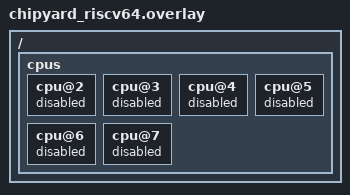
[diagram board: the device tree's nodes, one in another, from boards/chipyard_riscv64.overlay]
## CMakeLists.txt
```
# SPDX-License-Identifier: Apache-2.0
#
# Generic modelblaster harness. Build for a specific model+target by passing
# MODEL_DIR (where the generated C lives) and MODELBLASTER_BACKEND (the HW target):
#
#   west build -p -b spike_riscv64 modelblaster/harness -- \
#       -DMODEL_DIR=$PWD/modelblaster/examples/mlp/generated/scalar \
#       -DMODELBLASTER_BACKEND=scalar
#
# MODELBLASTER_BACKEND selects:
#   - the prj.conf overlay under modelblaster/harness/backends/<name>.conf
#   - the per-source compile flags applied to kernels.c
#   (both come from modelblaster/pipeline/backends.py — passed in via -D)
#
# Defaults to "scalar" if unset.

cmake_minimum_required(VERSION 3.20.0)

if(NOT DEFINED MODEL_DIR)
    message(FATAL_ERROR
        "MODEL_DIR not set. Pass -DMODEL_DIR=<absolute path to a generated/<target>/ dir>.")
endif()
get_filename_component(MODEL_DIR "${MODEL_DIR}" ABSOLUTE)
if(NOT IS_DIRECTORY "${MODEL_DIR}")
    message(FATAL_ERROR "MODEL_DIR='${MODEL_DIR}' is not a directory.")
endif()

if(NOT DEFINED MODELBLASTER_BACKEND)
    set(MODELBLASTER_BACKEND "scalar")
endif()

# Splice the backend prj.conf overlay BEFORE find_package(Zephyr) so its
# CONFIG_* lines reach Kconfig.
set(CONF_FILE "prj.conf")
set(_BACKEND_CONF "${CMAKE_CURRENT_LIST_DIR}/backends/${MODELBLASTER_BACKEND}.conf")
if(EXISTS "${_BACKEND_CONF}")
    list(APPEND CONF_FILE "${_BACKEND_CONF}")
else()
    message(FATAL_ERROR
        "MODELBLASTER_BACKEND='${MODELBLASTER_BACKEND}' but no overlay at ${_BACKEND_CONF}")
endif()

find_package(Zephyr REQUIRED HINTS $ENV{ZEPHYR_BASE})
project(modelblaster_harness)

foreach(_required model.c model.h kernels.c kernels.h weights.c weights.h buffers.c test_io.h test_io.S test_golden.bin)
    if(NOT EXISTS "${MODEL_DIR}/${_required}")
        message(FATAL_ERROR
            "MODEL_DIR='${MODEL_DIR}' is missing required file: ${_required}. "
            "Run modelblaster/pipeline/generate_skeleton.py and generate_kernels.py first.")
    endif()
endforeach()
# Test input blob(s): single-input models emit test_input.bin; multi-input
# models emit test_input0.bin, test_input1.bin, ... (each .incbin'd by
# test_io.S). Require at least one of the two forms to exist.
if(NOT EXISTS "${MODEL_DIR}/test_input.bin" AND NOT EXISTS "${MODEL_DIR}/test_input0.bin")
    message(FATAL_ERROR
        "MODEL_DIR='${MODEL_DIR}' has no test_input.bin or test_input0.bin. "
        "Run modelblaster/pipeline/generate_skeleton.py first.")
endif()
message(STATUS "modelblaster harness MODEL_DIR=${MODEL_DIR}  backend=${MODELBLASTER_BACKEND}")

target_sources(app PRIVATE
    src/main.c
    ${MODEL_DIR}/model.c
    ${MODEL_DIR}/kernels.c
    ${MODEL_DIR}/weights.c
    ${MODEL_DIR}/buffers.c
    ${MODEL_DIR}/test_io.S
)
set_source_files_properties(${MODEL_DIR}/test_io.S PROPERTIES LANGUAGE ASM)

# Big models (mlp_control's hidden layers, dronet's conv weights) push
# .sdata past the ±2KB window that the linker tries to fold into
# `gp`-relative loads via R_RISCV_GPREL_I, producing
# "relocation truncated to fit" against e.g. z_malloc_heap. Disable
# linker relaxation here — medany still gives ±2GB addressing, we just
# lose the gp-relative shortcut. No measurable code-size impact.
zephyr_link_libraries(-Wl,--no-relax)

# >2GB baked io only links under the RISC-V large code model
# (CONFIG_RISCV_CMODEL_LARGE), which fixes the C-side references. But the
# hand-written startup assembly (vector.S/reset.S/isr.S) uses fixed
# PC-relative addressing that -mcmodel=large does NOT rewrite, so if the
# giant io sits in .rodata (before .bss) it pushes gp/_kernel/z_interrupt_stacks
# past the startup asm's +/-2GiB reach and the link still truncates. When the
# large model is active, emit the io into .mb_bigio (test_io.S #ifdef
# MB_BIGIO_HIGH) and place that section ABOVE .bss (harness/bigio.ld). Default
# (medany) builds are untouched -> byte-identical.
# MB_NO_BIGIO_REORDER=1 opts out (io stays in .rodata) — e.g. io that fits
# under 2GiB, or XIP boards where io belongs in flash not RAM.
if(CONFIG_RISCV_CMODEL_LARGE AND NOT MB_NO_BIGIO_REORDER)
    target_compile_definitions(app PRIVATE MB_BIGIO_HIGH=1)
    zephyr_linker_sources(SECTIONS ${CMAKE_CURRENT_LIST_DIR}/bigio.ld)
    message(STATUS "modelblaster harness: CMODEL_LARGE active -> io in .mb_bigio placed above .bss")
endif()

target_include_directories(app PRIVATE
    src
    ${MODEL_DIR}
)

# Apply backend-specific compile flags ONLY to kernels.c so we don't perturb
# Zephyr's own build. Flags are passed in via -DMODELBLASTER_KERNEL_CFLAGS=...
# as a CMake list (semicolon-separated).
if(DEFINED MODELBLASTER_KERNEL_CFLAGS AND NOT "${MODELBLASTER_KERNEL_CFLAGS}" STREQUAL "")
    set_source_files_properties(
        ${MODEL_DIR}/kernels.c
        PROPERTIES COMPILE_OPTIONS "${MODELBLASTER_KERNEL_CFLAGS}"
    )
    message(STATUS "modelblaster harness kernel cflags=${MODELBLASTER_KERNEL_CFLAGS}")
endif()

# Opt-in: TACIT / L-Trace of just the model inference (brackets run_model with
# the encoder start/stop). Pass -DMB_TACIT_TRACE_MODEL=1 and run on the
# TACIT-enabled spike with `--trace=l`. See samples/tacit/TACIT_TRACING.md.
if(MB_TACIT_TRACE_MODEL)
    target_compile_definitions(app PRIVATE MB_TACIT_TRACE_MODEL=1)
    message(STATUS "modelblaster harness: TACIT model tracing enabled")
endif()
```

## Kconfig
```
# Application-level Kconfig for the ModelBlaster harness.
#
# Zephyr picks this up automatically when APPLICATION_SOURCE_DIR is this
# directory (see ZEPHYR/cmake/modules/kconfig.cmake L48-50). We use it to
# declare any project-local Kconfig symbols that aren't in the upstream
# Zephyr tree the workspace happens to ship, then source the standard
# Zephyr Kconfig so the rest of the build pulls in everything else.

# ---- ModelBlaster-local symbols ----

config RISCV_V_KERNEL_ONLY
	bool "Restrict V codegen to kernel files only"
	depends on RISCV_ISA_EXT_V
	default n
	help
	  Restrict V codegen to kernel files + arch/riscv/core/v.c only.
	  Without this, GCC auto-vectorizes struct-init/memset in vprintk,
	  libc, micro-ROS, broker, etc. via fractional-LMUL vector stores
	  — which on multi-hart Saturn FireSim makes scalar code paths
	  interrupt-corruptible (mid-V instruction preemption can clobber
	  scalar regs). We want V live ONLY inside the generated kernel
	  functions, where preemption is masked already (run_graph_b's
	  irq mask path).

	  Not required on single-hart spike runs (no preemption) but
	  must be y for FireSim multi-hart Saturn.

	  The actual enforcement (V codegen restriction) is opt-in: enabling
	  this symbol declares the intent and the build system / make rules
	  add -fno-tree-vectorize to the non-kernel TUs in the appropriate
	  passes. Upstream Zephyr doesn't have this option yet; tracked
	  under tmp/07_gotchas.md #9.

# ---- pull in standard Zephyr Kconfig ----

source "Kconfig.zephyr"
```

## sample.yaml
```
sample:
  description: Generated DNN inference harness (modelblaster flow)
  name: modelblaster_harness
common:
  tags: modelblaster dnn
  integration_platforms:
    - spike_riscv64
  harness: console
  harness_config:
    type: multi_line
    regex:
      - "=== MODELBLASTER_OUTPUT_BEGIN ==="
      - "=== MODELBLASTER_OUTPUT_END ==="
tests:
  sample.modelblaster.harness:
    tags: modelblaster
```

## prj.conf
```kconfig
# 4 MB main stack — large enough for im2col-style algorithms that allocate
# OH*OW * IC*KH*KW floats as a stack VLA. DroNet's worst case is about
# 295 KB; we leave plenty of headroom for larger models.
CONFIG_MAIN_STACK_SIZE=4194304
CONFIG_CBPRINTF_FP_SUPPORT=y
CONFIG_FPU=y
```

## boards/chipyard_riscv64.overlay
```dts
/*
 * DT overlay for FireSimGemminiAndOPUShuttleConfig.
 * Our SoC has only 2 Shuttle tiles, but chipyard-riscv64.dtsi declares 8 CPUs.
 * Disable the non-existent CPUs so Zephyr's SMP boot only tries to wake harts 0-1.
 * Lesson 1 in docs/dev_blog/2026-05-13-zephyr-on-hetero-shuttle-firesim.md.
 */

/ {
	cpus {
		cpu@2 { status = "disabled"; };
		cpu@3 { status = "disabled"; };
		cpu@4 { status = "disabled"; };
		cpu@5 { status = "disabled"; };
		cpu@6 { status = "disabled"; };
		cpu@7 { status = "disabled"; };
	};
};
```

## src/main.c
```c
/*
 * Copyright (c) 2026 Dima Nikiforov <vnikiforov@berkeley.edu>
 * SPDX-License-Identifier: Apache-2.0
 *
 * Modelblaster harness entry point. Runs a generated DNN model on a fixed
 * test input, validates the model output IN-BINARY against the baked-in
 * test_golden (already in rodata via test_io.S's .incbin), and prints
 * a single summary line for the host-side runner to parse.
 *
 * The on-device verify replaced an earlier per-element printf dump.
 * That dump was fast on spike (functional sim, fast HTIF UART) but
 * dominated FireSim runtime on real RTL (4k+ floats per bench at one
 * line each, several minutes per run). The summary path keeps spike
 * fast and lets FireSim re-rank candidates in seconds instead of
 * blowing the timeout.
 */

#include <stdio.h>
#include <stdlib.h>
#include <zephyr/kernel.h>
#if defined(CONFIG_RISCV_ISA_EXT_ZVT)
#include <zephyr/arch/riscv/zvt.h>
#endif
#include <zephyr/sys/reboot.h>

#include "model.h"
#include "test_io.h"

/* Opt-in TACIT / L-Trace of just the model inference. Enable by building with
 * -DMB_TACIT_TRACE_MODEL=1 (see CMakeLists.txt), then run on the TACIT-enabled
 * spike with `--trace=l`. Brackets only run_model() so the trace is the model's
 * control flow (not boot) -- preferable to CONFIG_STARTUP_TACIT for substantial
 * models. See samples/tacit/TACIT_TRACING.md. */
#if defined(MB_TACIT_TRACE_MODEL)
#include <tacit/tacit.h>
#include <zephyr/arch/cpu.h>
#endif

static model_output_t model_output[MODEL_OUTPUT_SIZE];

int main(void)
{
#if defined(CONFIG_SMP) && defined(CONFIG_RISCV_ISA_EXT_V) && (CONFIG_MP_MAX_NUM_CPUS > 1)
    /* Pin main to a hart that HAS vector hardware. Hart 0 boots without V
     * on the hetero bitstreams (GemminiAndOPUShuttleConfig,
     * chipyard_hetero_q31, firesim_rocket_saturn), so running a V-using
     * generated kernel from the boot hart would trap on the first
     * vsetvli. Pinning is a no-op on single-hart builds (e.g. spike)
     * because the guard requires MP_MAX_NUM_CPUS > 1.
     *
     * The default of 1 is right for the DUAL bitstreams. It is wrong for
     * f2_quad_hetero_norose_tacit_q31_60mhz, where the tiles physically
     * differ -- harts 0,1 are Rocket + Q0.31 Gemmini with NO vector,
     * harts 2,3 are Rocket + Saturn with NO Gemmini -- so a vector
     * kernel pinned to hart 1 traps there. Build that bitstream with
     * -DMODELBLASTER_PIN_HART=2.
     *
     * Requires CONFIG_SCHED_CPU_MASK_PIN_ONLY=y in the FireSim overlay
     * (harness/backends/firesim_chipyard.conf) — already set. */
#ifndef MODELBLASTER_PIN_HART
#define MODELBLASTER_PIN_HART 1
#endif
    k_thread_cpu_pin(k_current_get(), MODELBLASTER_PIN_HART);
#endif

#if defined(CONFIG_RISCV_ISA_EXT_ZVT)
    /* zvt backend: opt this (kernel-running) thread in to Zvt tile state.
     * Until then mstatus.MS=Off and every tile instruction faults. */
    {
        static Z_RISCV_ZVT_SAVE_AREA_DEFINE(mb_zvt_save_area);
        int zrc = arch_riscv_zvt_enable(mb_zvt_save_area, sizeof(mb_zvt_save_area));
        if (zrc != 0) {
            printf("modelblaster harness: arch_riscv_zvt_enable failed (%d)\n", zrc);
            return 0;
        }
    }
#endif

    printf("modelblaster harness: model=%s in=%d out=%d\n",
           MODEL_NAME, MODEL_INPUT_SIZE, MODEL_OUTPUT_SIZE);

    /* Single-model harness has no thread pool — pass NULL. The
     * generated kernel bodies ignore it; only the parallel-for wrapper
     * (when emitted) would dispatch onto a real modelblaster_pool_t.
     * model_run_test() feeds the baked test input(s) — it is arity-agnostic
     * (1 input or N typed inputs), so this call is unchanged across models. */
#if defined(MB_TACIT_TRACE_MODEL)
    LTraceEncoderType *_tacit_enc = l_trace_encoder_get(arch_curr_cpu()->id);
    l_trace_encoder_configure_target(_tacit_enc, TARGET_PRINT);
    l_trace_encoder_start(_tacit_enc);
#endif
    /* ------------------------------------------------------------------
     * MODELBLASTER_MASK_IRQ_DURING_RUN: run the whole inference with
     * machine interrupts masked.
     *
     * WHY. On the Saturn RVV configs in this tree (measured on
     * f2_dual_small_norose_tacit_q31_60mhz, VLEN=256/dLen=128) a trap
     * taken while a vector kernel is executing can come back with
     * EXACTLY ONE scalar register corrupted. It is deterministic and
     * bit-reproducible, and it is invisible on spike. Two shipped fp16
     * conv kernels were blamed for it before the trap path was:
     *
     *   ViNT depthwise_conv2d_f16 : mcause 5, mtval 0x7aa61300c on a
     *     `vlse16.v v2,(a0),t6` whose a0 the kernel's own arithmetic
     *     provably cannot compute -- every other register in the frame
     *     is exactly right for that iteration (fq jobs 248/249/271).
     *   ViNT conv2d_f16           : mcause 4, mtval 3 on the same kind
     *     of strided weight gather (fq jobs 248/290/292).
     *
     * Masking MIE for the duration of the run removes both, with the
     * model otherwise byte-identical (fq jobs 283/285). The kernels
     * themselves are clean: all 81 ViNT conv shapes run fault-free in
     * isolation on the same bitstream (fq jobs 270/296).
     *
     * COST. No preemption and no tick servicing for the duration of one
     * model_run_test(). This harness is single-threaded and main() is
     * pinned to one hart, so nothing else is runnable; k_cycle_get_64()
     * reads free-running mtime and stays correct, and the per-op rdcycle
     * profile gets cleaner (no ISR time folded in). A harness that runs
     * a thread pool or several models concurrently must NOT do this --
     * hence the switch rather than an unconditional lock.
     * ------------------------------------------------------------------ */
#if !defined(MODELBLASTER_MASK_IRQ_DURING_RUN)
#define MODELBLASTER_MASK_IRQ_DURING_RUN 1
#endif
#if MODELBLASTER_MASK_IRQ_DURING_RUN
    unsigned int mb_irq_key = irq_lock();
#endif

    model_run_test(model_output, NULL);
#if defined(MB_TACIT_TRACE_MODEL)
    l_trace_encoder_stop(_tacit_enc);
    for (int _i = 0; _i < 16; _i++) { __asm__ volatile("nop"); } /* flush */
#endif
    /* RVV->scalar visibility barrier. The kernels write model_output via RVV
     * vector stores (vse/vsse); the verify loop below reads it with scalar
     * loads. On FireSim/Saturn's weak memory model the vector store buffer may
     * not have drained before the scalar reads -> stale/partial output ->
     * spurious miscompute (correct on spike, wrong on FireSim; worse in
     * complex kernels with more in-flight stores). Same root cause + fix as the
     * ExecuTorch riscv_executor_runner fence. */
#if defined(__riscv)
    __asm__ volatile("fence rw, rw" ::: "memory");
#else
    /* board native_sim/native/64 is this same harness built by the HOST
     * compiler, where `fence rw, rw` is not an instruction and the whole
     * build fails here. There is no vector store buffer to drain on x86;
     * a compiler barrier is all the ordering that case needs. */
    __atomic_thread_fence(__ATOMIC_SEQ_CST);
#endif

#if MODELBLASTER_MASK_IRQ_DURING_RUN
    irq_unlock(mb_irq_key);
#endif

    /* In-binary golden compare.
     *
     * Both `model_output[i]` and `model_test_golden[i]` are widened to
     * float for the comparison so the same loop body works for f32,
     * f16, and integer outputs. We track the global max absolute error
     * and max relative error; the host gates on
     *
     *   (max_abs_err <= atol) || (max_rel_err <= rtol)
     *
     * which is a sufficient PASS condition for numpy.allclose-style
     * tolerance — every element satisfies at least one bound globally,
     * so it satisfies them element-wise too. Conservative vs the
     * per-element threshold but correct, and avoids shipping the full
     * tensor over UART. */
    float max_abs_err = 0.0f;
    float max_rel_err = 0.0f;
    for (int i = 0; i < MODEL_TEST_OUTPUT_LEN; i++) {
        float a = (float)model_output[i];
        float g = (float)model_test_golden[i];
        float ae = a > g ? a - g : g - a;
        float ag = g > 0.0f ? g : -g;
        float re = ae / (ag > 1e-12f ? ag : 1e-12f);
        if (ae > max_abs_err) max_abs_err = ae;
        if (re > max_rel_err) max_rel_err = re;
    }
    printf("=== MODELBLASTER_VERIFY === max_abs_err=%.9g max_rel_err=%.9g n=%d\n",
           (double)max_abs_err, (double)max_rel_err, MODEL_TEST_OUTPUT_LEN);

    /* Optional: dump the raw model output buffer so the host can
     * compare in domain-specific units (e.g. waypoint coordinates for
     * a navigation policy, not int8 LSBs). Guarded on output size to
     * avoid blowing past FIRESIM_TIMEOUT on detection-class models
     * (yolov8's ~75k-element output would take ~10s over HTIF). The
     * Per-element format is printf("%.9g\n", ...) — host parses one
     * float per line between BEGIN / END markers. */
#if !defined(MODELBLASTER_DUMP_OUTPUT_MAX_ELEMS)
#define MODELBLASTER_DUMP_OUTPUT_MAX_ELEMS 256
#endif
    if (MODEL_TEST_OUTPUT_LEN <= MODELBLASTER_DUMP_OUTPUT_MAX_ELEMS) {
        printf("=== MODELBLASTER_OUTPUT_BEGIN ===\n");
        for (int i = 0; i < MODEL_TEST_OUTPUT_LEN; i++) {
            printf("%.9g\n", (double)(float)model_output[i]);
        }
        printf("=== MODELBLASTER_OUTPUT_END ===\n");
    }

    /* Per-kernel profile (rdcycle deltas, populated by run_model). */
    int n_records = 0;
    const model_op_record_t *records = model_profile_records(&n_records);
    printf("=== MODELBLASTER_PROFILE_BEGIN ===\n");
    printf("dispatch_id,name,op,shape,cycles\n");
    for (int i = 0; i < n_records; i++) {
        printf("%d,%s,%s,%s,%lu\n",
               records[i].dispatch_id,
               records[i].name, records[i].op, records[i].shape,
               records[i].cycles);
    }
    printf("=== MODELBLASTER_PROFILE_END ===\n");

    /* Wall-clock total for the run (k_cycle_get_64 / mtime delta). The
     * runner reads this line to get the cross-hart-correct number;
     * per-op rdcycle deltas above are used for relative comparisons. */
    printf("=== MODELBLASTER_WALL_CYCLES === %lu\n", model_wall_cycles());

#ifdef CONFIG_ARCH_POSIX
    /* native_sim: no HTIF/reboot — terminate the host process cleanly so the
     * native runner gets a clean exit (stdout already flushed above). */
    exit(0);
#else
    sys_reboot(SYS_REBOOT_COLD);
#endif
    return 0;
}
```
